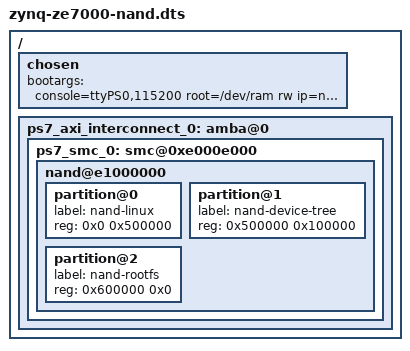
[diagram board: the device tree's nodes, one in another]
/*
 * microZed DTS file header for ramdisk boot.
 */

/dts-v1/;
/include/ "zynq-ze7000.dtsi"
/ {
	chosen {
		bootargs = "console=ttyPS0,115200 root=/dev/ram rw ip=none earlyprintk";
	} ;
	ps7_axi_interconnect_0: amba@0 {

		ps7_smc_0: smc@0xe000e000 {

			nand@e1000000 {

				partition@0 {
					label = "nand-linux";
					reg = <0x0 0x500000>;
				} ;

				partition@1 {
					label = "nand-device-tree";
					reg = <0x500000 0x100000>;
				} ;

				partition@2 {
					label = "nand-rootfs";
					reg = <0x600000 0x0>; /* maximum size */
				} ;
			} ;
		} ;

	} ;
} ;
